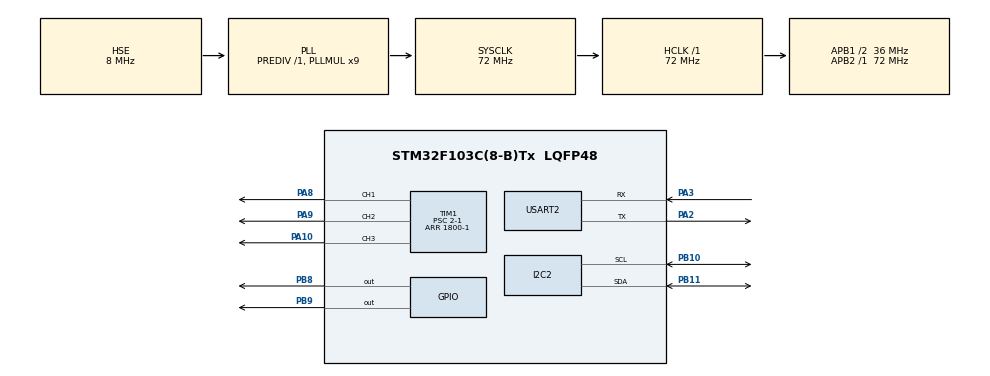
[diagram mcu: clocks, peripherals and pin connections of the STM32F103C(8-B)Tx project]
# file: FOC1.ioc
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Mcu.Family=STM32F1
Mcu.Name=STM32F103C(8-B)Tx
Mcu.Package=LQFP48
NVIC.PriorityGroup=NVIC_PRIORITYGROUP_4
NVIC.TIM4_IRQn=true\:0\:0\:false\:false\:true\:true\:true\:true
PA10.Signal=S_TIM1_CH3
PA13.Mode=Serial_Wire
PA13.Signal=SYS_JTMS-SWDIO
PA14.Mode=Serial_Wire
PA14.Signal=SYS_JTCK-SWCLK
PA2.Mode=Asynchronous
PA2.Signal=USART2_TX
PA3.Mode=Asynchronous
PA3.Signal=USART2_RX
PA8.Signal=S_TIM1_CH1
PA9.Signal=S_TIM1_CH2
PB10.Mode=I2C
PB10.Signal=I2C2_SCL
PB11.Mode=I2C
PB11.Signal=I2C2_SDA
PB8.GPIO_ModeDefaultOutputPP=GPIO_MODE_OUTPUT_OD
PB8.GPIO_PuPd=GPIO_NOPULL
PB8.Signal=GPIO_Output
PB9.GPIO_ModeDefaultOutputPP=GPIO_MODE_OUTPUT_OD
PB9.GPIO_PuPd=GPIO_NOPULL
PB9.Signal=GPIO_Output
PD0-OSC_IN.Mode=HSE-External-Oscillator
PD0-OSC_IN.Signal=RCC_OSC_IN
PD1-OSC_OUT.Mode=HSE-External-Oscillator
PD1-OSC_OUT.Signal=RCC_OSC_OUT
ProjectManager.HeapSize=0x200
ProjectManager.StackSize=0x400
ProjectManager.TargetToolchain=CMake
RCC.AHBFreq_Value=72000000
RCC.APB1CLKDivider=RCC_HCLK_DIV2
RCC.APB1Freq_Value=36000000
RCC.APB1TimFreq_Value=72000000
RCC.APB2Freq_Value=72000000
RCC.APB2TimFreq_Value=72000000
RCC.HCLKFreq_Value=72000000
RCC.PLLMUL=RCC_PLL_MUL9
RCC.PLLSourceVirtual=RCC_PLLSOURCE_HSE
RCC.SYSCLKFreq_VALUE=72000000
RCC.SYSCLKSource=RCC_SYSCLKSOURCE_PLLCLK
RCC.USBFreq_Value=72000000
SH.S_TIM1_CH1.0=TIM1_CH1,PWM Generation1 CH1
SH.S_TIM1_CH2.0=TIM1_CH2,PWM Generation2 CH2
SH.S_TIM1_CH3.0=TIM1_CH3,PWM Generation3 CH3
TIM1.Channel-PWM\ Generation1\ CH1=TIM_CHANNEL_1
TIM1.Channel-PWM\ Generation2\ CH2=TIM_CHANNEL_2
TIM1.Channel-PWM\ Generation3\ CH3=TIM_CHANNEL_3
TIM1.CounterMode=TIM_COUNTERMODE_CENTERALIGNED3
TIM1.Period=1800-1
TIM1.Prescaler=2-1
TIM4.Period=65535
TIM4.Prescaler=36000-1
USART2.VirtualMode=VM_ASYNC
VP_TIM1_VS_ClockSourceINT.Mode=Internal
VP_TIM4_VS_ClockSourceINT.Mode=Internal
board=custom

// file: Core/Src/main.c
/* USER CODE BEGIN Header */
/**
  ******************************************************************************
  * @file           : main.c
  * @brief          : Main program body
  ******************************************************************************
  * @attention
  *
  * Copyright (c) 2026 STMicroelectronics.
  * All rights reserved.
  *
  * This software is licensed under terms that can be found in the LICENSE file
  * in the root directory of this software component.
  * If no LICENSE file comes with this software, it is provided AS-IS.
  *
  ******************************************************************************
  */
/* USER CODE END Header */
#include "main.h"
#include "i2c.h"
#include "tim.h"
#include "usart.h"
#include "gpio.h"

/* USER CODE BEGIN Includes */
#include "OLED.h"
#include "BLDC.h"
#include "AS5600.h"
#include <stdint.h>
/* USER CODE END Includes */

void SystemClock_Config(void);

/* USER CODE BEGIN 0 */
/*
uint8_t TIM4_Overflow_Count = 0; // 定时器4溢出计数器
void HAL_TIM_PeriodElapsedCallback(TIM_HandleTypeDef *htim)
{
  if (htim->Instance == TIM4) // 判断是否为定时器4的中断
  {
    TIM4_Overflow_Count ++; // 定时器4溢出计数器加1
    Set_TarAngle(0); // 定时器4溢出时调用位置控制函数，目标角度为0
  }
}

uint8_t Return_Overflow_Count(void)
{
  uint8_t TIM4_Overflow_Count1 = TIM4_Overflow_Count;
  TIM4_Overflow_Count = 0; // 重置溢出计数器
  return TIM4_Overflow_Count1;
}

*/
/* USER CODE END 0 */

int main(void)
{

  /* MCU Configuration--------------------------------------------------------*/

  /* Reset of all peripherals, Initializes the Flash interface and the Systick. */
  HAL_Init();

  /* Configure the system clock */
  SystemClock_Config();

  /* Initialize all configured peripherals */
  MX_GPIO_Init();
  MX_TIM1_Init();
  MX_USART2_UART_Init();
  MX_TIM4_Init();
  MX_I2C2_Init();
  /* USER CODE BEGIN 2 */
  OLED_Init();
  BLDC_Init();
  OLED_ShowString(0, 0, "BLDC", OLED_8X16);
  OLED_Update();
  float Angle = 0.0f;
  float Angle_NO_TRACK = 0.0f;//随便写测试git的注释
  /* USER CODE END 2 */

  /* Infinite loop */
  /* USER CODE BEGIN WHILE */
  while (1)
  {
    Angle = GetAngle();
    Angle_NO_TRACK = GetAngle_Without_Track();
    // velocity_open_loop(-50);
    Set_TarAngle(M_PI);
    // OLED_Printf(0, 16, OLED_8X16, "Angle = %4.2f", Angle);
    // OLED_Printf(0, 32, OLED_8X16, "Angle = %4.2f", Angle_NO_TRACK);
    // OLED_Update();

    // velocity_open_loop(50);
    /* USER CODE END WHILE */

  }
}

void SystemClock_Config(void)
{
  RCC_OscInitTypeDef RCC_OscInitStruct = {0};
  RCC_ClkInitTypeDef RCC_ClkInitStruct = {0};

  /** Initializes the RCC Oscillators according to the specified parameters
  * in the RCC_OscInitTypeDef structure.
  */
  RCC_OscInitStruct.OscillatorType = RCC_OSCILLATORTYPE_HSE;
  RCC_OscInitStruct.HSEState = RCC_HSE_ON;
  RCC_OscInitStruct.HSEPredivValue = RCC_HSE_PREDIV_DIV1;
  RCC_OscInitStruct.HSIState = RCC_HSI_ON;
  RCC_OscInitStruct.PLL.PLLState = RCC_PLL_ON;
  RCC_OscInitStruct.PLL.PLLSource = RCC_PLLSOURCE_HSE;
  RCC_OscInitStruct.PLL.PLLMUL = RCC_PLL_MUL9;
  if (HAL_RCC_OscConfig(&RCC_OscInitStruct) != HAL_OK)
  {
    Error_Handler();
  }

  /** Initializes the CPU, AHB and APB buses clocks
  */
  RCC_ClkInitStruct.ClockType = RCC_CLOCKTYPE_HCLK|RCC_CLOCKTYPE_SYSCLK
                              |RCC_CLOCKTYPE_PCLK1|RCC_CLOCKTYPE_PCLK2;
  RCC_ClkInitStruct.SYSCLKSource = RCC_SYSCLKSOURCE_PLLCLK;
  RCC_ClkInitStruct.AHBCLKDivider = RCC_SYSCLK_DIV1;
  RCC_ClkInitStruct.APB1CLKDivider = RCC_HCLK_DIV2;
  RCC_ClkInitStruct.APB2CLKDivider = RCC_HCLK_DIV1;

  if (HAL_RCC_ClockConfig(&RCC_ClkInitStruct, FLASH_LATENCY_2) != HAL_OK)
  {
    Error_Handler();
  }
}

void Error_Handler(void)
{
  __disable_irq();
  while (1)
  {
  }
}
